# M3U0 register map
File version: 0.1
TOSHIBA Cortex-M3 MCU
Registers are 32-bit, read-write, no defined reset value unless marked. A register's access mark holds for its fields unless they carry their own. Offsets are from the block's base; lines under a group give offsets from that group; [hi:lo] are bit positions; {n}, {i} and the like mark numbered series; 'fields as' and 'values as' point back to an identical list; <NAME> marks a mode.

## Memory map
0x40000040 PB blocks up to offset 0x3C — General Purpose Input_Output Port (PB)
0x40000100 PE blocks up to offset 0x3C — General Purpose Input_Output Port (PE)
0x40000140 PF blocks up to offset 0x3C — General Purpose Input_Output Port (PF)
0x40000180 PG blocks up to offset 0x3C — General Purpose Input_Output Port (PG)
0x40000240 PJ blocks up to offset 0x3C — General Purpose Input_Output Port (PJ)
0x40000280 PK blocks up to offset 0x3C — General Purpose Input_Output Port (PK)
0x40000300 PM blocks up to offset 0x3C — General Purpose Input_Output Port (PM)
0x40010000 TB0 size 0x30 — 16-bit Timer_Event Counter (TB)
0x40010100 TB4 size 0x30
0x40010140 TB5 size 0x30
0x400101C0 TB7 size 0x30
0x40010400 EN size 0x10 — Encoder Input (ENC)
0x40020000 SBI size 0x18 — Serial BusInterface(SBI)
0x40020080 SC0 size 0x34 — Serial Channel (SC)
0x400200C0 SC1 size 0x34
0x40030200 AD blocks up to offset 0xD8 — Analog-to-Digital Converter (AD)
0x40030400 AMP blocks up to offset 0x1C — Ope-AMP control
0x40040000 WD size 0x8 — Watchdog Timer (WD)
0x40040200 CG blocks up to offset 0x24 — Clock Generator (CG)
0x40040300 TRMOSC size 0x10 — Internal High-speed Oscillation Adjustment
0x40040800 OFD size 0x18 — Oscillation Frequency Detector (OFD)
0x40040900 VD size 0x4 — Low Voltage Detection Circuit
0x40050000 VE blocks up to offset 0x1BC — Vector Engine (VE)
0x40050480 PMD size 0x68 — 16-bit Multi-Purpose Timer (MPT-PMD)
0x40060000 NF size 0x8 — DigitalNoizeFilterClockControl
0x41FFF010 FC blocks up to offset 0x24 — Flash Control (FC)

## PB — General Purpose Input_Output Port (PB)
Base 0x40000040
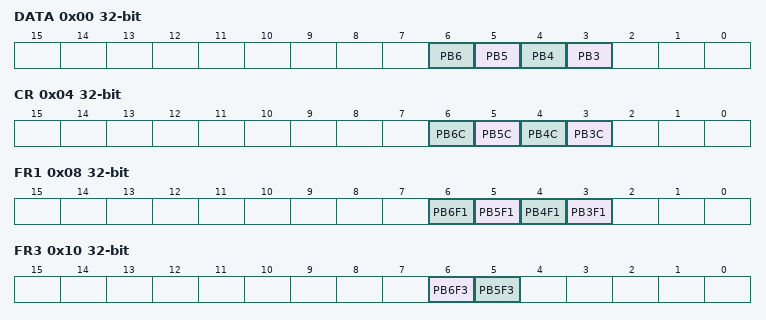
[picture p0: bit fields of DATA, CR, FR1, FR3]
0x00 DATA — PB Register
  [n] PB{n} (n=3..6)
0x04 CR — PB Control Register
  [n] PB{n}C (n=3..6)
0x08 FR1 — PB Function Register 1
  [n] PB{n}F1 (n=3..6)
0x0C FR2 — PB Function Register 2
  [6] PB6F2
0x10 FR3 — PB Function Register 3
  [6] PB6F3, [5] PB5F3
0x14 FR4 — PB Function Register 4
  [6] PB6F4
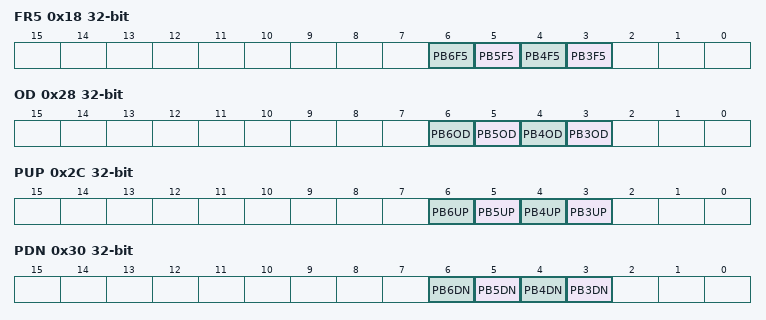
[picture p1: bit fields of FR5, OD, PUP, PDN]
0x18 FR5 — PB Function Register 5
  [n] PB{n}F5 (n=3..6)
0x28 OD — PB Open Drain Control Register
  [n] PB{n}OD (n=3..6)
0x2C PUP — PB Pull-Up Control Register
  [n] PB{n}UP (n=3..6)
0x30 PDN — PB Pull-Down Control Register
  [n] PB{n}DN (n=3..6)
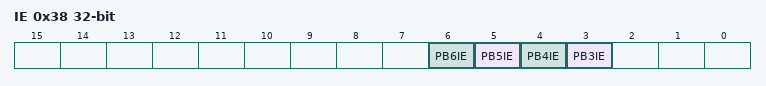
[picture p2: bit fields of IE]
0x38 IE — PB Input Enable Control Register
  [n] PB{n}IE (n=3..6)

## PE — General Purpose Input_Output Port (PE)
Base 0x40000100
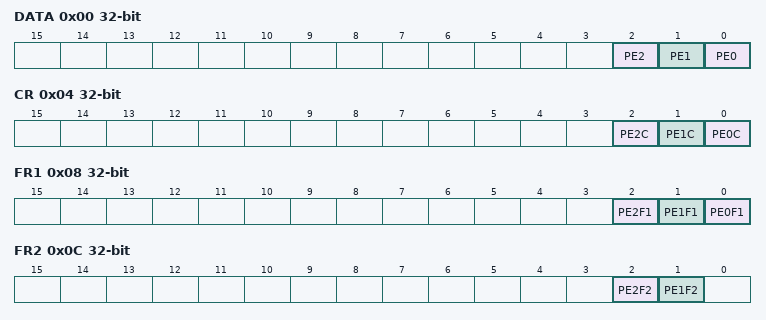
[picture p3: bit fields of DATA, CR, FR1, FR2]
0x00 DATA — PE Register
  [2] PE2, [1] PE1, [0] PE0
0x04 CR — PE Control Register
  [2] PE2C, [1] PE1C, [0] PE0C
0x08 FR1 — PE Function Register 1
  [2] PE2F1, [1] PE1F1, [0] PE0F1
0x0C FR2 — PE Function Register 2
  [2] PE2F2, [1] PE1F2
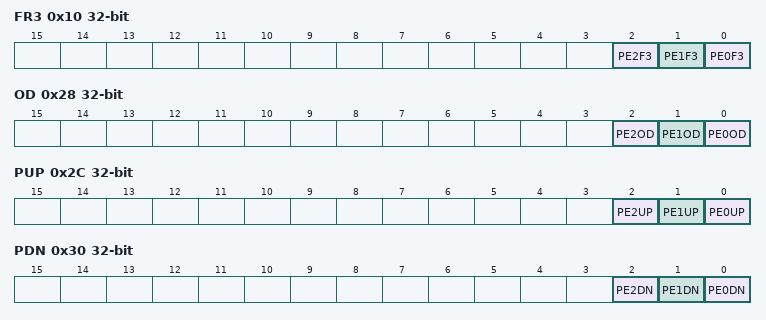
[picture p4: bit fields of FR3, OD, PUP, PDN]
0x10 FR3 — PE Function Register 3
  [2] PE2F3, [1] PE1F3, [0] PE0F3
0x14 FR4 — PE Function Register 4
  [2] PE2F4
0x18 FR5 — PE Function Register 5
  [2] PE2F5
0x28 OD — PE Open Drain Control Register
  [2] PE2OD, [1] PE1OD, [0] PE0OD
0x2C PUP — PE Pull-Up Control Register
  [2] PE2UP, [1] PE1UP, [0] PE0UP
0x30 PDN — PE Pull-Down Control Register
  [2] PE2DN, [1] PE1DN, [0] PE0DN
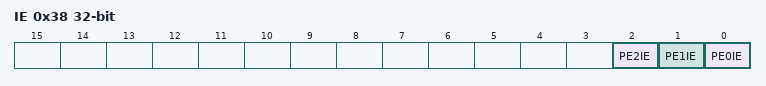
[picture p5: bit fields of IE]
0x38 IE — PE Input Enable Control Register
  [2] PE2IE, [1] PE1IE, [0] PE0IE

## PF — General Purpose Input_Output Port (PF)
Base 0x40000140
0x00 DATA — PF Register
  [0] PF0
0x04 CR — PF Control Register
  [0] PF0C
0x08 FR1 — PF Function Register 1
  [0] PF0F1
0x0C FR2 — PF Function Register 2
  [0] PF0F2
0x14 FR4 — PF Function Register 4
  [1] PF0F4
0x18 FR5 — PF Function Register 5
  [1] PF0F5
0x28 OD — PF Open Drain Control Register
  [0] PF0OD
0x2C PUP — PF Pull-Up Control Register
  [0] PF0UP
0x30 PDN — PF Pull-Down Control Register
  [0] PF0DN
0x38 IE — PF Input Enable Control Register
  [0] PF0IE
